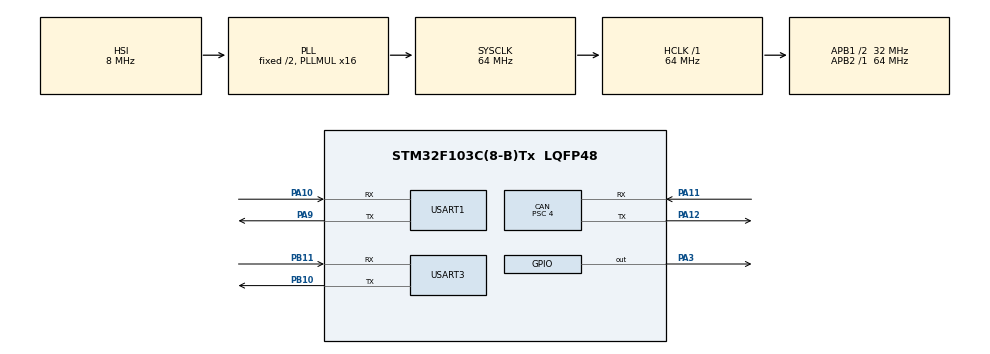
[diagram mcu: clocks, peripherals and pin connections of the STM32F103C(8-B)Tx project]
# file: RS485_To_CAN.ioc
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CAN.BS1=CAN_BS1_13TQ
CAN.BS2=CAN_BS2_2TQ
CAN.CalculateBaudRate=500000
CAN.CalculateTimeBit=2000
CAN.CalculateTimeQuantum=125.0
CAN.Prescaler=4
Mcu.Family=STM32F1
Mcu.Name=STM32F103C(8-B)Tx
Mcu.Package=LQFP48
NVIC.CAN1_RX1_IRQn=true\:0\:0\:false\:false\:true\:true\:true\:true
NVIC.CAN1_SCE_IRQn=true\:0\:0\:false\:false\:true\:true\:true\:true
NVIC.PriorityGroup=NVIC_PRIORITYGROUP_4
PA10.Mode=Asynchronous
PA10.Signal=USART1_RX
PA11.Mode=CAN_Activate
PA11.Signal=CAN_RX
PA12.Mode=CAN_Activate
PA12.Signal=CAN_TX
PA13.Mode=Serial_Wire
PA13.Signal=SYS_JTMS-SWDIO
PA14.Mode=Serial_Wire
PA14.Signal=SYS_JTCK-SWCLK
PA3.Signal=GPIO_Output
PA9.Mode=Asynchronous
PA9.Signal=USART1_TX
PB10.Mode=Asynchronous
PB10.Signal=USART3_TX
PB11.Mode=Asynchronous
PB11.Signal=USART3_RX
ProjectManager.HeapSize=0x200
ProjectManager.StackSize=0x400
ProjectManager.TargetToolchain=MDK-ARM V5.32
RCC.AHBFreq_Value=64000000
RCC.APB1CLKDivider=RCC_HCLK_DIV2
RCC.APB1Freq_Value=32000000
RCC.APB1TimFreq_Value=64000000
RCC.APB2Freq_Value=64000000
RCC.APB2TimFreq_Value=64000000
RCC.HCLKFreq_Value=64000000
RCC.PLLMUL=RCC_PLL_MUL16
RCC.SYSCLKFreq_VALUE=64000000
RCC.SYSCLKSource=RCC_SYSCLKSOURCE_PLLCLK
RCC.USBFreq_Value=64000000
USART1.VirtualMode=VM_ASYNC
USART3.VirtualMode=VM_ASYNC
board=custom

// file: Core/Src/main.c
/* USER CODE BEGIN Header */
/**
  ******************************************************************************
  * @file           : main.c
  * @brief          : Main program body
  ******************************************************************************
  * @attention
  *
  * Copyright (c) 2026 STMicroelectronics.
  * All rights reserved.
  *
  * This software is licensed under terms that can be found in the LICENSE file
  * in the root directory of this software component.
  * If no LICENSE file comes with this software, it is provided AS-IS.
  *
  ******************************************************************************
  */
/* USER CODE END Header */
#include "main.h"
#include "can.h"
#include "usart.h"
#include "gpio.h"

/* USER CODE BEGIN Includes */
#include "fsd13_rs485.h"
#include "stdio.h"
/* USER CODE END Includes */

void SystemClock_Config(void);

int main(void)
{

  /* MCU Configuration--------------------------------------------------------*/

  /* Reset of all peripherals, Initializes the Flash interface and the Systick. */
  HAL_Init();

  /* Configure the system clock */
  SystemClock_Config();

  /* Initialize all configured peripherals */
  MX_GPIO_Init();
  MX_CAN_Init();
  MX_USART1_UART_Init();
  MX_USART3_UART_Init();
  /* USER CODE BEGIN 2 */
// 初始化传感器：FSD13-100型号，Modbus RTU协议
  FSD13_Init(FSD13_100, PROTOCOL_MODBUS);

// 打开激光
  FSD13_LaserOn();
  HAL_Delay(500);  // 等待激光稳定

  float distance;
  char buf[64];
  /* USER CODE END 2 */

  /* Infinite loop */
  /* USER CODE BEGIN WHILE */
  while (1)
  {
     if(FSD13_ReadDistance(&distance) == 0) {
            // 读取成功，distance单位mm

        } else {

        }

        HAL_Delay(100);  // 10Hz采样
    /* USER CODE END WHILE */

  }
}

void SystemClock_Config(void)
{
  RCC_OscInitTypeDef RCC_OscInitStruct = {0};
  RCC_ClkInitTypeDef RCC_ClkInitStruct = {0};

  /** Initializes the RCC Oscillators according to the specified parameters
  * in the RCC_OscInitTypeDef structure.
  */
  RCC_OscInitStruct.OscillatorType = RCC_OSCILLATORTYPE_HSI;
  RCC_OscInitStruct.HSIState = RCC_HSI_ON;
  RCC_OscInitStruct.HSICalibrationValue = RCC_HSICALIBRATION_DEFAULT;
  RCC_OscInitStruct.PLL.PLLState = RCC_PLL_ON;
  RCC_OscInitStruct.PLL.PLLSource = RCC_PLLSOURCE_HSI_DIV2;
  RCC_OscInitStruct.PLL.PLLMUL = RCC_PLL_MUL16;
  if (HAL_RCC_OscConfig(&RCC_OscInitStruct) != HAL_OK)
  {
    Error_Handler();
  }

  /** Initializes the CPU, AHB and APB buses clocks
  */
  RCC_ClkInitStruct.ClockType = RCC_CLOCKTYPE_HCLK|RCC_CLOCKTYPE_SYSCLK
                              |RCC_CLOCKTYPE_PCLK1|RCC_CLOCKTYPE_PCLK2;
  RCC_ClkInitStruct.SYSCLKSource = RCC_SYSCLKSOURCE_PLLCLK;
  RCC_ClkInitStruct.AHBCLKDivider = RCC_SYSCLK_DIV1;
  RCC_ClkInitStruct.APB1CLKDivider = RCC_HCLK_DIV2;
  RCC_ClkInitStruct.APB2CLKDivider = RCC_HCLK_DIV1;

  if (HAL_RCC_ClockConfig(&RCC_ClkInitStruct, FLASH_LATENCY_2) != HAL_OK)
  {
    Error_Handler();
  }
}

void Error_Handler(void)
{
  __disable_irq();
  while (1)
  {
  }
}
